VERSION ""

NS_ :

BS_:

BU_: XXX

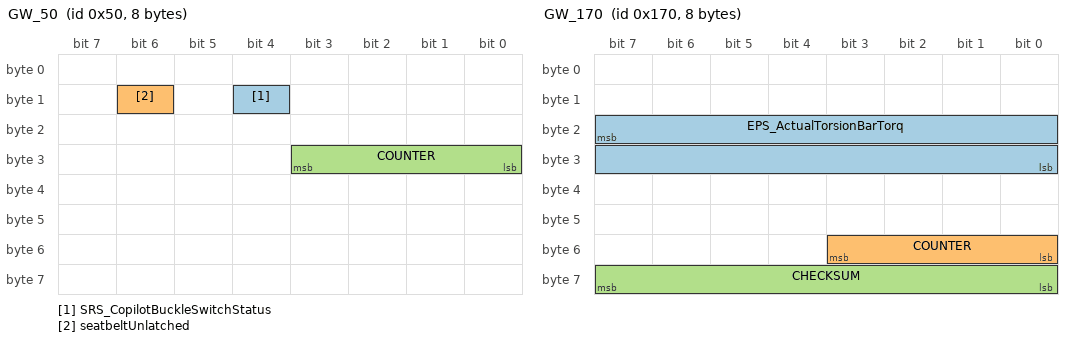
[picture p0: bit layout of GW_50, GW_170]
BO_ 80 GW_50: 8 XXX
 SG_ SRS_CopilotBuckleSwitchStatus : 12|1@0+ (1,0) [0|1] "" XXX
 SG_ seatbeltUnlatched : 14|1@0+ (1,0) [0|1] "" XXX
 SG_ COUNTER : 27|4@0+ (1,0) [0|15] "" XXX

BO_ 368 GW_170: 8 ESP
 SG_ EPS_ActualTorsionBarTorq : 23|16@0+ (1,-5533) [0|65535] "" XXX
 SG_ COUNTER : 51|4@0+ (1,0) [0|15] "" XXX
 SG_ CHECKSUM : 63|8@0+ (1,0) [0|255] "" XXX

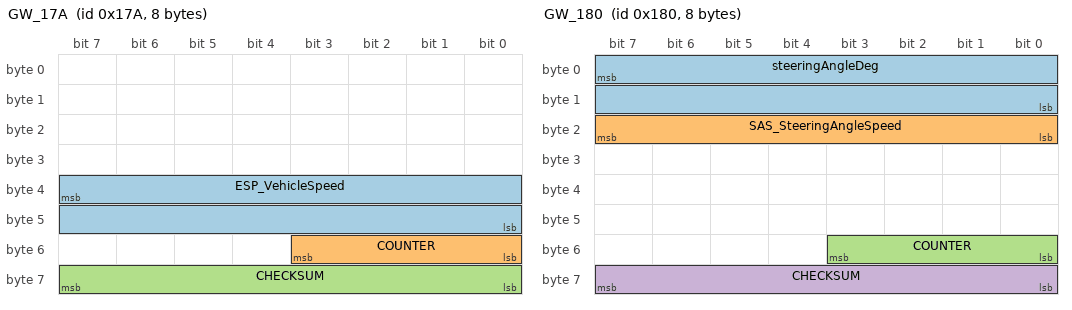
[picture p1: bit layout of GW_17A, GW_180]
BO_ 378 GW_17A: 8 XXX
 SG_ ESP_VehicleSpeed : 39|16@0+ (0.05,0) [0|65535] "km/h" XXX
 SG_ COUNTER : 51|4@0+ (1,0) [0|15] "" XXX
 SG_ CHECKSUM : 63|8@0+ (1,0) [0|255] "" XXX

BO_ 382 GW_17E: 8 XXX
 SG_ sig_033 : 7|8@0+ (1,0) [0|255] "" XXX
 SG_ sig_034 : 15|8@0+ (1,0) [0|255] "" XXX
 SG_ sig_035 : 23|8@0+ (1,0) [0|255] "" XXX
 SG_ sig_036 : 31|8@0+ (1,0) [0|255] "" XXX
 SG_ sig_037 : 39|8@0+ (1,0) [0|255] "" XXX
 SG_ sig_038 : 40|1@0+ (1,0) [0|1] "" XXX
 SG_ sig_039 : 41|1@0+ (1,0) [0|1] "" XXX
 SG_ sig_040 : 42|1@0+ (1,0) [0|1] "" XXX
 SG_ sig_041 : 43|1@0+ (1,0) [0|1] "" XXX
 SG_ sig_042 : 51|4@0+ (1,0) [0|15] "" XXX
 SG_ sig_043 : 63|8@0+ (1,0) [0|255] "" XXX
 SG_ EPS_MeasuredTorsionBarTorque : 7|12@0+ (0.001,0) [0|4095] "" XXX
 SG_ EPS_RollingCounter_17E : 51|4@0+ (1,0) [0|15] "" XXX
 SG_ EPS_LatCtrlAvailabilityStatus : 55|2@0+ (1,0) [0|3] "" XXX
 SG_ CHECKSUM : 63|8@0+ (1,0) [0|255] "" XXX

BO_ 384 GW_180: 8 XXX
 SG_ steeringAngleDeg : 7|16@0- (0.1,0) [-476|476] "deg" XXX
 SG_ SAS_SteeringAngleSpeed : 23|8@0+ (1,0) [0|255] "" XXX
 SG_ COUNTER : 51|4@0+ (1,0) [0|15] "" XXX
 SG_ CHECKSUM : 63|8@0+ (1,0) [0|255] "" XXX

BO_ 388 NEW_MSG_184: 8 XXX

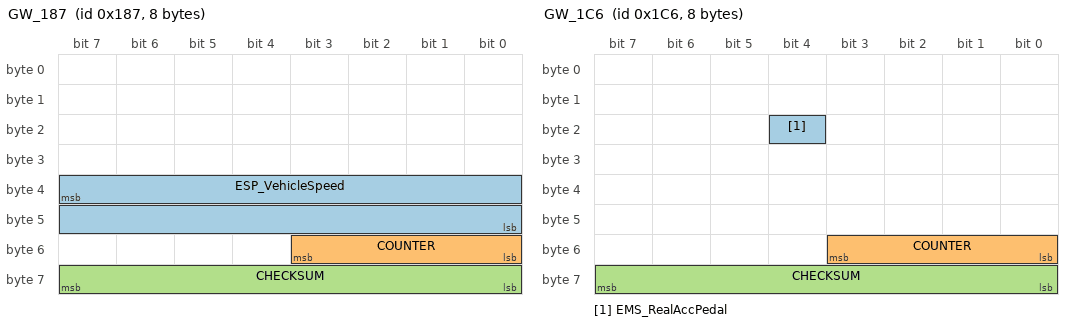
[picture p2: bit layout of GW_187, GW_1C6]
BO_ 391 GW_187: 8 XXX
 SG_ ESP_VehicleSpeed : 39|16@0+ (0.05,0) [0|65535] "km/h" XXX
 SG_ COUNTER : 51|4@0+ (1,0) [0|15] "" XXX
 SG_ CHECKSUM : 63|8@0+ (1,0) [0|255] "" XXX

BO_ 392 NEW_MSG_188: 8 XXX
 SG_ NEW_SIGNAL_1 : 7|16@0+ (1,0) [0|65535] "" XXX

BO_ 406 GW_196: 8 XXX
 SG_ EMS_BrakePedalStatus : 0|1@0+ (1,0) [0|1] "" XXX
 SG_ EMS_RealAccPedal : 20|1@0+ (1,0) [0|1] "" XXX
 SG_ brakePressed : 0|1@0+ (1,0) [0|1] "" XXX
 SG_ gasPressed : 20|1@0+ (1,0) [0|1] "" XXX
 SG_ COUNTER : 51|4@0+ (1,0) [0|15] "" XXX
 SG_ CHECKSUM : 63|8@0+ (1,0) [0|255] "" XXX

BO_ 422 GW_1A6: 8 XXX
 SG_ EMS_BrakePedalStatus : 4|1@0+ (1,0) [0|1] "" XXX
 SG_ EMS_RealAccPedal : 16|1@0+ (1,0) [0|1] "" XXX
 SG_ brakePressed : 4|1@0+ (1,0) [0|1] "" XXX
 SG_ gasPressed : 16|1@0+ (1,0) [0|1] "" XXX
 SG_ COUNTER : 51|4@0+ (1,0) [0|15] "" XXX
 SG_ CHECKSUM : 63|8@0+ (1,0) [0|255] "" XXX

BO_ 442 GW_1BA: 8 XXX
 SG_ sig_075 : 7|8@0- (0.1,0) [-12.8|12.7] "" XXX
 SG_ sig_076 : 15|8@0- (0.1,0) [-12.8|12.7] "" XXX
 SG_ sig_077 : 31|16@0- (0.1,0) [-476|476] "deg" XXX
 SG_ sig_078 : 16|1@0+ (1,0) [0|1] "" XXX
 SG_ sig_079 : 51|4@0+ (1,0) [0|15] "" XXX
 SG_ sig_080 : 63|8@0+ (1,0) [0|255] "" XXX
 SG_ STEER_LIMIT_Down : 7|8@0- (0.1,0) [-12.8|12.7] "" XXX
 SG_ STEER_LIMIT_Up : 15|8@0- (0.1,0) [-12.8|12.7] "" XXX
 SG_ ACC_SteeringAngleReq_1BA : 16|1@0+ (1,0) [0|1] "" XXX
 SG_ ACC_SteeringAngleSub_1BA : 31|16@0- (0.1,0) [-476|476] "deg" XXX
 SG_ Counter_1BA : 51|4@0+ (1,0) [0|15] "" XXX
 SG_ CHECKSUM : 63|8@0+ (1,0) [0|255] "" XXX

BO_ 454 GW_1C6: 8 XXX
 SG_ EMS_RealAccPedal : 20|1@0+ (1,0) [0|1] "" XXX
 SG_ COUNTER : 51|4@0+ (1,0) [0|15] "" XXX
 SG_ CHECKSUM : 63|8@0+ (1,0) [0|255] "" XXX

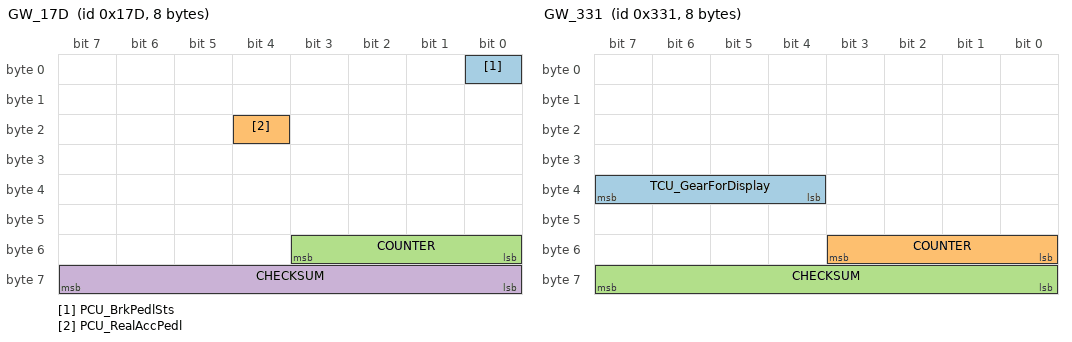
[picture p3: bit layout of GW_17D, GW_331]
BO_ 381 GW_17D: 8 XXX
 SG_ PCU_BrkPedlSts : 0|1@0+ (1,0) [0|1] "" XXX
 SG_ PCU_RealAccPedl : 20|1@0+ (1,0) [0|1] "" XXX
 SG_ COUNTER : 51|4@0+ (1,0) [0|15] "" XXX
 SG_ CHECKSUM : 63|8@0+ (1,0) [0|255] "" XXX

BO_ 817 GW_331: 8 XXX
 SG_ TCU_GearForDisplay : 39|4@0+ (1,-7) [0|15] "" XXX
 SG_ COUNTER : 51|4@0+ (1,0) [0|15] "" XXX
 SG_ CHECKSUM : 63|8@0+ (1,0) [0|255] "" XXX

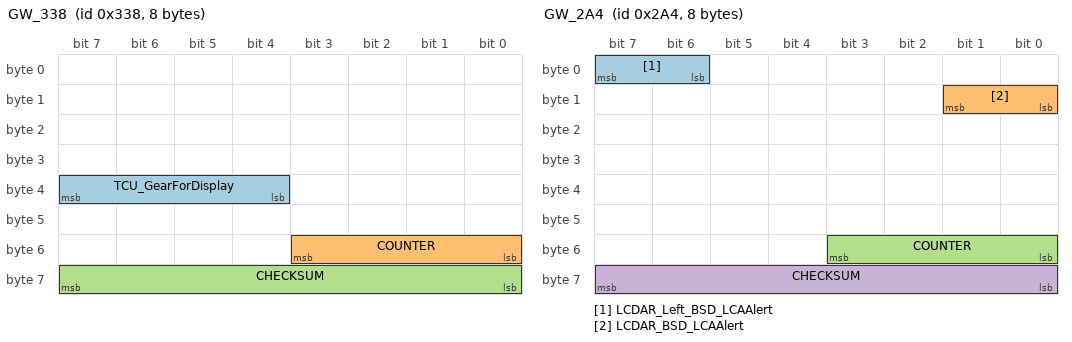
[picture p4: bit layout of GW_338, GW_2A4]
BO_ 824 GW_338: 8 XXX
 SG_ TCU_GearForDisplay : 39|4@0+ (1,-7) [0|15] "" XXX
 SG_ COUNTER : 51|4@0+ (1,0) [0|15] "" XXX
 SG_ CHECKSUM : 63|8@0+ (1,0) [0|255] "" XXX

BO_ 676 GW_2A4: 8 XXX
 SG_ LCDAR_Left_BSD_LCAAlert : 7|2@0+ (1,0) [0|3] "" XXX
 SG_ LCDAR_BSD_LCAAlert : 9|2@0+ (1,0) [0|3] "" XXX
 SG_ COUNTER : 51|4@0+ (1,0) [0|15] "" XXX
 SG_ CHECKSUM : 63|8@0+ (1,0) [0|255] "" XXX

BO_ 518 NEW_MSG_206: 8 XXX
 SG_ NEW_SIGNAL_1 : 7|16@0+ (0.78125,0) [0|65535] "" XXX

BO_ 520 NEW_MSG_208: 8 XXX
 SG_ NEW_SIGNAL_1 : 7|16@0+ (0.78125,0) [0|65535] "" XXX

BO_ 580 GW_244: 32 XXX
 SG_ sig_081 : 7|16@0- (0.05,0) [-10|10] "m/s2" XXX
 SG_ sig_082 : 23|8@0+ (1,0) [0|255] "" XXX
 SG_ sig_083 : 31|8@0+ (1,0) [0|255] "" XXX
 SG_ sig_084 : 32|1@0+ (1,0) [0|1] "" XXX
 SG_ sig_085 : 33|1@0+ (1,0) [0|1] "" XXX
 SG_ sig_086 : 34|1@0+ (1,0) [0|1] "" XXX
 SG_ sig_087 : 35|1@0+ (1,0) [0|1] "" XXX
 SG_ sig_088 : 36|1@0+ (1,0) [0|1] "" XXX
 SG_ sig_089 : 37|1@0+ (1,0) [0|1] "" XXX
 SG_ sig_090 : 38|1@0+ (1,0) [0|1] "" XXX
 SG_ sig_091 : 39|3@0+ (1,0) [0|7] "" XXX
 SG_ sig_092 : 51|4@0+ (1,0) [0|15] "" XXX
 SG_ sig_093 : 63|8@0+ (1,0) [0|255] "" XXX
 SG_ sig_094 : 71|8@0+ (1,0) [0|255] "" XXX
 SG_ sig_095 : 79|8@0+ (1,0) [0|255] "" XXX
 SG_ sig_096 : 87|8@0+ (1,0) [0|255] "" XXX
 SG_ sig_097 : 95|8@0+ (1,0) [0|255] "" XXX
 SG_ sig_098 : 96|1@0+ (1,0) [0|1] "" XXX
 SG_ sig_099 : 103|16@0- (1,-5000) [-10000|10000] "" XXX
 SG_ sig_100 : 104|1@0+ (1,0) [0|1] "" XXX
 SG_ sig_101 : 105|1@0+ (1,0) [0|1] "" XXX
 SG_ sig_102 : 106|1@0+ (1,0) [0|1] "" XXX
 SG_ sig_103 : 115|4@0+ (1,0) [0|15] "" XXX
 SG_ sig_104 : 127|8@0+ (1,0) [0|255] "" XXX
 SG_ sig_105 : 135|8@0+ (1,0) [0|255] "" XXX
 SG_ sig_106 : 143|8@0+ (1,0) [0|255] "" XXX
 SG_ sig_107 : 151|8@0+ (1,0) [0|255] "" XXX
 SG_ sig_108 : 159|8@0+ (1,0) [0|255] "" XXX
 SG_ ACC_Acceleration_24E : 7|16@0- (0.05,0) [-10|10] "m/s2" XXX
 SG_ ACC_AEBCtrlType : 86|3@0+ (1,0) [0|7] "" XXX
 SG_ ACC_FCWPreWarning : 87|1@0+ (1,0) [0|1] "" XXX
 SG_ ACC_ACCEnable : 98|1@0+ (1,0) [0|1] "" XXX
 SG_ ACC_RollingCounter_24E : 51|4@0+ (1,0) [0|15] "" XXX
 SG_ ACC_ACCMode : 39|3@0+ (1,0) [0|7] "" XXX
 SG_ ACC_ACCReq : 98|1@0+ (1,0) [0|1] "" XXX
 SG_ CHECKSUM : 63|8@0+ (1,0) [0|255] "" XXX
 SG_ COUNTER_1 : 115|4@0+ (1,0) [0|15] "" XXX
 SG_ CHECKSUM_1 : 127|8@0+ (1,0) [0|255] "" XXX

BO_ 588 NEW_MSG_24C: 8 XXX
 SG_ NEW_SIGNAL_1 : 7|16@0+ (1,0) [0|65535] "" XXX

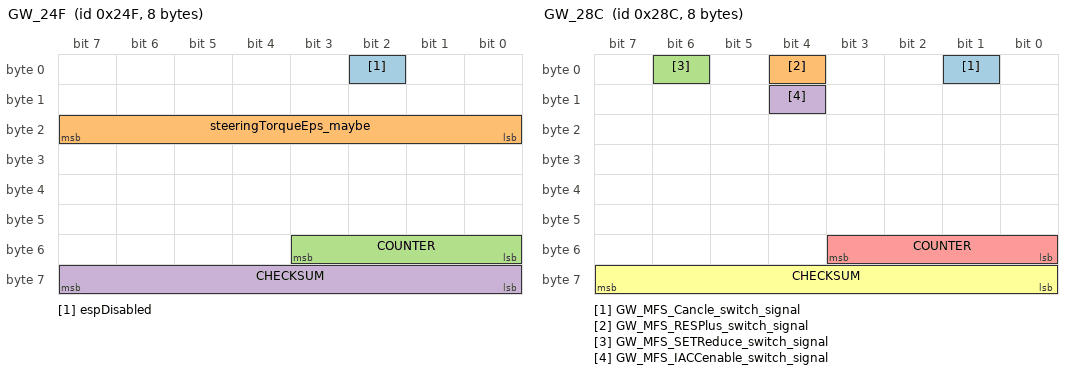
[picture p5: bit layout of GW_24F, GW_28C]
BO_ 591 GW_24F: 8 XXX
 SG_ espDisabled : 2|1@0+ (1,0) [0|1] "" XXX
 SG_ steeringTorqueEps_maybe : 23|8@0- (0.1,0) [0|255] "" XXX
 SG_ COUNTER : 51|4@0+ (1,0) [0|15] "" XXX
 SG_ CHECKSUM : 63|8@0+ (1,0) [0|255] "" XXX

BO_ 651 GW_28B: 8 XXX
 SG_ BCM_TurnIndicatorRight : 19|2@0+ (1,0) [0|3] "" XXX
 SG_ BCM_TurnIndicatorLeft : 22|2@0+ (1,0) [0|3] "" XXX
 SG_ BCM_DriverDoorStatus : 23|1@0+ (1,0) [0|1] "" XXX
 SG_ rightBlinker : 19|2@0+ (1,0) [0|3] "" XXX
 SG_ leftBlinker : 22|2@0+ (1,0) [0|3] "" XXX
 SG_ doorOpen : 23|1@0+ (1,0) [0|1] "" XXX
 SG_ COUNTER : 51|4@0+ (1,0) [0|15] "" XXX
 SG_ CHECKSUM : 63|8@0+ (1,0) [0|255] "" XXX

BO_ 652 GW_28C: 8 XXX
 SG_ GW_MFS_Cancle_switch_signal : 1|1@0+ (1,0) [0|1] "" XXX
 SG_ GW_MFS_RESPlus_switch_signal : 4|1@0+ (1,0) [0|1] "" XXX
 SG_ GW_MFS_SETReduce_switch_signal : 6|1@0+ (1,0) [0|1] "" XXX
 SG_ GW_MFS_IACCenable_switch_signal : 12|1@0+ (1,0) [0|1] "" XXX
 SG_ COUNTER : 51|4@0+ (1,0) [0|15] "" XXX
 SG_ CHECKSUM : 63|8@0+ (1,0) [0|255] "" XXX

BO_ 775 GW_307: 64 XXX
 SG_ sig_336 : 7|16@0+ (0.0078125,0) [0|250] "km/h" XXX
 SG_ sig_337 : 16|1@0+ (1,0) [0|1] "" XXX
 SG_ sig_338 : 17|1@0+ (1,0) [0|1] "" XXX
 SG_ sig_339 : 18|2@0+ (1,0) [0|3] "" XXX
 SG_ sig_340 : 20|1@0+ (1,0) [0|1] "" XXX
 SG_ sig_341 : 21|1@0+ (1,0) [0|1] "" XXX
 SG_ sig_342 : 51|4@0+ (1,0) [0|15] "" XXX
 SG_ sig_343 : 63|8@0+ (1,0) [0|255] "" XXX
 SG_ sig_344 : 71|8@0+ (1,0) [0|255] "" XXX
 SG_ sig_345 : 79|8@0+ (1,0) [0|255] "" XXX
 SG_ sig_346 : 115|4@0+ (1,0) [0|15] "" XXX
 SG_ sig_347 : 127|8@0+ (1,0) [0|255] "" XXX
 SG_ sig_348 : 179|4@0+ (1,0) [0|15] "" XXX
 SG_ sig_349 : 191|8@0+ (1,0) [0|255] "" XXX
 SG_ sig_350 : 199|8@0+ (1,0) [0|255] "" XXX
 SG_ sig_351 : 207|8@0+ (1,0) [0|255] "" XXX
 SG_ sig_352 : 215|8@0+ (1,0) [0|255] "" XXX
 SG_ sig_353 : 223|8@0+ (1,0) [0|255] "" XXX
 SG_ sig_354 : 243|4@0+ (1,0) [0|15] "" XXX
 SG_ sig_355 : 255|8@0+ (1,0) [0|255] "" XXX
 SG_ sig_356 : 263|8@0+ (1,0) [0|255] "" XXX
 SG_ sig_357 : 271|8@0+ (1,0) [0|255] "" XXX
 SG_ sig_358 : 279|8@0+ (1,0) [0|255] "" XXX
 SG_ sig_359 : 287|8@0+ (1,0) [0|255] "" XXX
 SG_ sig_360 : 295|8@0+ (1,0) [0|255] "" XXX
 SG_ sig_361 : 303|8@0+ (1,0) [0|255] "" XXX
 SG_ sig_362 : 311|8@0+ (1,0) [0|255] "" XXX
 SG_ sig_363 : 319|8@0+ (1,0) [0|255] "" XXX
 SG_ sig_364 : 327|8@0+ (1,0) [0|255] "" XXX
 SG_ sig_365 : 335|8@0+ (1,0) [0|255] "" XXX
 SG_ sig_366 : 343|8@0+ (1,0) [0|255] "" XXX
 SG_ sig_367 : 351|8@0+ (1,0) [0|255] "" XXX
 SG_ sig_368 : 359|8@0+ (1,0) [0|255] "" XXX
 SG_ sig_369 : 367|8@0+ (1,0) [0|255] "" XXX
 SG_ sig_370 : 375|8@0+ (1,0) [0|255] "" XXX
 SG_ sig_371 : 383|8@0+ (1,0) [0|255] "" XXX
 SG_ sig_372 : 391|8@0+ (1,0) [0|255] "" XXX
 SG_ sig_373 : 399|8@0+ (1,0) [0|255] "" XXX
 SG_ sig_374 : 407|8@0+ (1,0) [0|255] "" XXX
 SG_ sig_375 : 415|8@0+ (1,0) [0|255] "" XXX
 SG_ vCruise : 7|16@0+ (0.0078125,0) [0|250] "km/h" XXX
 SG_ ACC_DistanceLevel : 18|2@0+ (1,0) [0|3] "" XXX
 SG_ Counter_35E : 51|4@0+ (1,0) [0|15] "" XXX
 SG_ CHECKSUM_1 : 63|8@0+ (1,0) [0|255] "" XXX
 SG_ COUNTER_2 : 115|4@0+ (1,0) [0|15] "" XXX
 SG_ CHECKSUM_2 : 127|8@0+ (1,0) [0|255] "" XXX
 SG_ COUNTER_3 : 179|4@0+ (1,0) [0|15] "" XXX
 SG_ CHECKSUM_3 : 191|8@0+ (1,0) [0|255] "" XXX
 SG_ COUNTER_4 : 243|4@0+ (1,0) [0|15] "" XXX
 SG_ CHECKSUM_4 : 255|8@0+ (1,0) [0|255] "" XXX

BO_ 794 GW_31A: 64 XXX
 SG_ sig_386 : 7|8@0+ (1,0) [0|255] "" XXX
 SG_ sig_387 : 15|8@0+ (1,0) [0|255] "" XXX
 SG_ sig_388 : 23|8@0+ (1,0) [0|255] "" XXX
 SG_ sig_389 : 31|8@0+ (1,0) [0|255] "" XXX
 SG_ sig_390 : 32|1@0+ (1,0) [0|1] "" XXX
 SG_ sig_391 : 33|1@0+ (1,0) [0|1] "" XXX
 SG_ sig_392 : 34|1@0+ (1,0) [0|1] "" XXX
 SG_ sig_393 : 35|1@0+ (1,0) [0|1] "" XXX
 SG_ sig_394 : 36|1@0+ (1,0) [0|1] "" XXX
 SG_ sig_395 : 51|4@0+ (1,0) [0|15] "" XXX
 SG_ sig_396 : 63|8@0+ (1,0) [0|255] "" XXX
 SG_ sig_397 : 71|8@0+ (1,0) [0|255] "" XXX
 SG_ sig_398 : 72|1@0+ (1,0) [0|1] "" XXX
 SG_ sig_399 : 73|1@0+ (1,0) [0|1] "" XXX
 SG_ sig_400 : 74|1@0+ (1,0) [0|1] "" XXX
 SG_ sig_401 : 75|1@0+ (1,0) [0|1] "" XXX
 SG_ sig_402 : 76|1@0+ (1,0) [0|1] "" XXX
 SG_ sig_403 : 77|1@0+ (1,0) [0|1] "" XXX
 SG_ sig_404 : 78|1@0+ (1,0) [0|1] "" XXX
 SG_ sig_405 : 79|1@0+ (1,0) [0|1] "" XXX
 SG_ sig_406 : 115|4@0+ (1,0) [0|15] "" XXX
 SG_ sig_407 : 127|8@0+ (1,0) [0|255] "" XXX
 SG_ sig_408 : 135|3@0+ (1,0) [0|7] "" XXX
 SG_ sig_409 : 138|1@0+ (1,0) [0|1] "" XXX
 SG_ sig_410 : 139|1@0+ (1,0) [0|1] "" XXX
 SG_ sig_411 : 140|2@0+ (1,0) [0|3] "" XXX
 SG_ sig_412 : 142|1@0+ (1,0) [0|1] "" XXX
 SG_ sig_413 : 143|1@0+ (1,0) [0|1] "" XXX
 SG_ sig_414 : 144|1@0+ (1,0) [0|1] "" XXX
 SG_ sig_415 : 179|4@0+ (1,0) [0|15] "" XXX
 SG_ sig_416 : 191|8@0+ (1,0) [0|255] "" XXX
 SG_ sig_417 : 199|8@0+ (1,0) [0|255] "" XXX
 SG_ sig_418 : 207|8@0+ (1,0) [0|255] "" XXX
 SG_ sig_419 : 215|8@0+ (1,0) [0|255] "" XXX
 SG_ sig_420 : 223|8@0+ (1,0) [0|255] "" XXX
 SG_ sig_421 : 231|8@0+ (1,0) [0|255] "" XXX
 SG_ sig_422 : 243|4@0+ (1,0) [0|15] "" XXX
 SG_ sig_423 : 255|8@0+ (1,0) [0|255] "" XXX
 SG_ Counter_36D : 51|4@0+ (1,0) [0|15] "" XXX
 SG_ CHECKSUM_1 : 63|8@0+ (1,0) [0|255] "" XXX
 SG_ cruiseState : 390|1@0+ (1,0) [0|1] "" XXX
 SG_ steeringPressed : 398|1@0+ (1,0) [0|1] "" XXX
 SG_ ACC_IACCHWAEnable : 390|1@0+ (1,0) [0|1] "" XXX
 SG_ COUNTER_2 : 115|4@0+ (1,0) [0|15] "" XXX
 SG_ CHECKSUM_2 : 127|8@0+ (1,0) [0|255] "" XXX
 SG_ ACC_IACCHWAMode : 135|3@0+ (1,0) [0|7] "" XXX
 SG_ COUNTER_3 : 179|4@0+ (1,0) [0|15] "" XXX
 SG_ CHECKSUM_3 : 191|8@0+ (1,0) [0|255] "" XXX
 SG_ COUNTER_4 : 243|4@0+ (1,0) [0|15] "" XXX
 SG_ CHECKSUM_4 : 255|8@0+ (1,0) [0|255] "" XXX

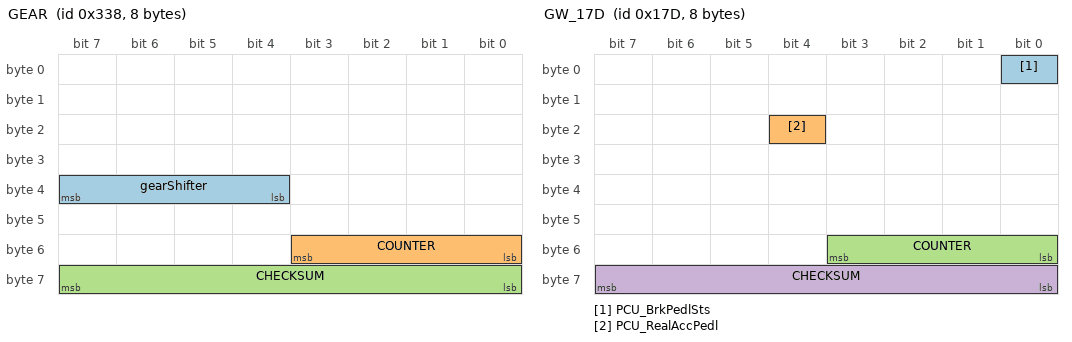
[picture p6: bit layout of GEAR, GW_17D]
BO_ 824 GEAR: 8 XXX
 SG_ gearShifter : 39|4@0+ (1,-7) [0|15] "" XXX
 SG_ COUNTER : 51|4@0+ (1,0) [0|15] "" XXX
 SG_ CHECKSUM : 63|8@0+ (1,0) [0|255] "" XXX

BO_ 999 NEW_MSG_3E7: 8 XXX
 SG_ NEW_SIGNAL_1 : 7|16@0+ (0.78,0) [0|65535] "" XXX

CM_ BO_ 378 "Z6 idd speed";
CM_ SG_ 384 steeringAngleDeg "1";
CM_ SG_ 422 brakePressed "IDD";
CM_ BO_ 591 "EPS_591";
CM_ SG_ 651 rightBlinker "2 right";
CM_ SG_ 651 leftBlinker "1 left";
CM_ SG_ 651 doorOpen "0 open";
CM_ BO_ 652 "GW_28C";
CM_ BO_ 824 "gear info";
VAL_ 824 TCU_GearForDisplay 2 "N" 1 "R" 3 "D" 0 "P";

BO_ 381 GW_17D: 8 XXX
 SG_ PCU_BrkPedlSts : 0|1@0+ (1,0) [0|1] "" XXX
 SG_ PCU_RealAccPedl : 20|1@0+ (1,0) [0|1] "" XXX
 SG_ COUNTER : 51|4@0+ (1,0) [0|15] "" XXX
 SG_ CHECKSUM : 63|8@0+ (1,0) [0|255] "" XXX

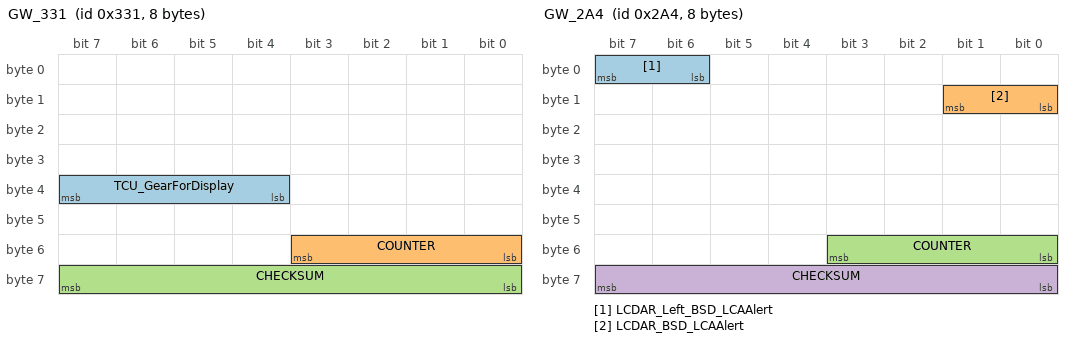
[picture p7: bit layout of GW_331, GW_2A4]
BO_ 817 GW_331: 8 XXX
 SG_ TCU_GearForDisplay : 39|4@0+ (1,-7) [0|15] "" XXX
 SG_ COUNTER : 51|4@0+ (1,0) [0|15] "" XXX
 SG_ CHECKSUM : 63|8@0+ (1,0) [0|255] "" XXX

BO_ 676 GW_2A4: 8 XXX
 SG_ LCDAR_Left_BSD_LCAAlert : 7|2@0+ (1,0) [0|3] "" XXX
 SG_ LCDAR_BSD_LCAAlert : 9|2@0+ (1,0) [0|3] "" XXX
 SG_ COUNTER : 51|4@0+ (1,0) [0|15] "" XXX
 SG_ CHECKSUM : 63|8@0+ (1,0) [0|255] "" XXX

CM_ BO_ 381 "QIYUAN A05 pedal data";
CM_ BO_ 817 "QIYUAN A05 gear info";
CM_ BO_ 676 "QIYUAN A05 blind spot detection";
VAL_ 817 TCU_GearForDisplay 2 "N" 1 "R" 3 "D" 0 "P";
